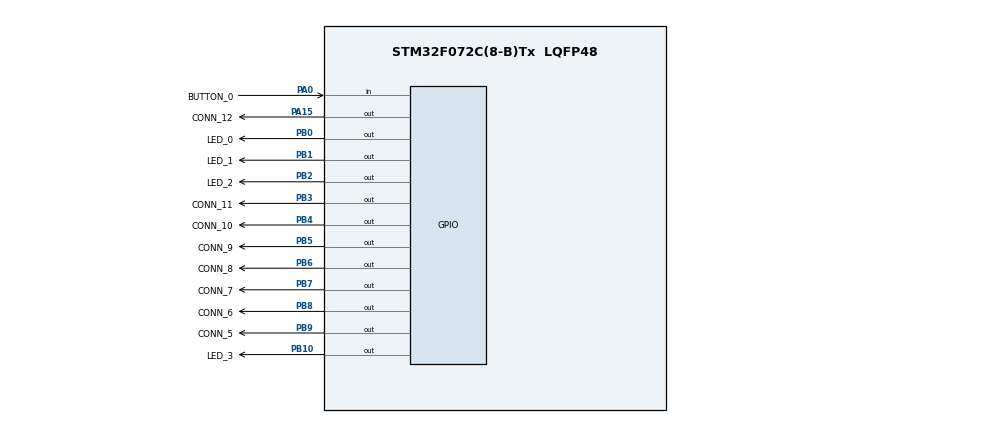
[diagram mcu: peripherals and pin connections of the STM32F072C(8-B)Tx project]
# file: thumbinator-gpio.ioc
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Mcu.Family=STM32F0
Mcu.Name=STM32F072C(8-B)Tx
Mcu.Package=LQFP48
PA0.GPIO_Label=BUTTON_0
PA0.GPIO_PuPd=GPIO_PULLUP
PA0.Signal=GPIO_Input
PA13.Mode=Serial_Wire
PA13.Signal=SYS_SWDIO
PA14.Mode=Serial_Wire
PA14.Signal=SYS_SWCLK
PA15.GPIO_Label=CONN_12
PA15.Signal=GPIO_Output
PB0.GPIO_Label=LED_0
PB0.Signal=GPIO_Output
PB1.GPIO_Label=LED_1
PB1.Signal=GPIO_Output
PB10.GPIO_Label=LED_3
PB10.Signal=GPIO_Output
PB2.GPIO_Label=LED_2
PB2.Signal=GPIO_Output
PB3.GPIO_Label=CONN_11
PB3.Signal=GPIO_Output
PB4.GPIO_Label=CONN_10
PB4.Signal=GPIO_Output
PB5.GPIO_Label=CONN_9
PB5.Signal=GPIO_Output
PB6.GPIO_Label=CONN_8
PB6.Signal=GPIO_Output
PB7.GPIO_Label=CONN_7
PB7.Signal=GPIO_Output
PB8.GPIO_Label=CONN_6
PB8.Signal=GPIO_Output
PB9.GPIO_Label=CONN_5
PB9.Signal=GPIO_Output
ProjectManager.HeapSize=0x200
ProjectManager.StackSize=0x400
ProjectManager.TargetToolchain=SW4STM32
board=thumbinator-gpio

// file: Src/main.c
/**
  ******************************************************************************
  * File Name          : main.c
  * Description        : Main program body
  ******************************************************************************
  ** This notice applies to any and all portions of this file
  * that are not between comment pairs USER CODE BEGIN and
  * USER CODE END. Other portions of this file, whether
  * inserted by the user or by software development tools
  * are owned by their respective copyright owners.
  *
  * COPYRIGHT(c) 2017 STMicroelectronics
  *
  * Redistribution and use in source and binary forms, with or without modification,
  * are permitted provided that the following conditions are met:
  *   1. Redistributions of source code must retain the above copyright notice,
  *      this list of conditions and the following disclaimer.
  *   2. Redistributions in binary form must reproduce the above copyright notice,
  *      this list of conditions and the following disclaimer in the documentation
  *      and/or other materials provided with the distribution.
  *   3. Neither the name of STMicroelectronics nor the names of its contributors
  *      may be used to endorse or promote products derived from this software
  *      without specific prior written permission.
  *
  * THIS SOFTWARE IS PROVIDED BY THE COPYRIGHT HOLDERS AND CONTRIBUTORS "AS IS"
  * AND ANY EXPRESS OR IMPLIED WARRANTIES, INCLUDING, BUT NOT LIMITED TO, THE
  * IMPLIED WARRANTIES OF MERCHANTABILITY AND FITNESS FOR A PARTICULAR PURPOSE ARE
  * DISCLAIMED. IN NO EVENT SHALL THE COPYRIGHT HOLDER OR CONTRIBUTORS BE LIABLE
  * FOR ANY DIRECT, INDIRECT, INCIDENTAL, SPECIAL, EXEMPLARY, OR CONSEQUENTIAL
  * DAMAGES (INCLUDING, BUT NOT LIMITED TO, PROCUREMENT OF SUBSTITUTE GOODS OR
  * SERVICES; LOSS OF USE, DATA, OR PROFITS; OR BUSINESS INTERRUPTION) HOWEVER
  * CAUSED AND ON ANY THEORY OF LIABILITY, WHETHER IN CONTRACT, STRICT LIABILITY,
  * OR TORT (INCLUDING NEGLIGENCE OR OTHERWISE) ARISING IN ANY WAY OUT OF THE USE
  * OF THIS SOFTWARE, EVEN IF ADVISED OF THE POSSIBILITY OF SUCH DAMAGE.
  *
  ******************************************************************************
  */
#include "main.h"
#include "stm32f0xx_hal.h"

/* USER CODE BEGIN PV */
/* Private variables ---------------------------------------------------------*/

/* USER CODE END PV */

void SystemClock_Config(void);
static void MX_GPIO_Init(void);

/* USER CODE BEGIN PFP */
/* Private function prototypes -----------------------------------------------*/

/* USER CODE END PFP */

/* USER CODE BEGIN 0 */

static void next_led(void) {
  static int i = 0;
  i = (i + 1) % 16;
  HAL_GPIO_WritePin(LED_0_GPIO_Port, LED_0_Pin, (i & 1) ? GPIO_PIN_SET : GPIO_PIN_RESET);
  HAL_GPIO_WritePin(LED_1_GPIO_Port, LED_1_Pin, (i & 2) ? GPIO_PIN_SET : GPIO_PIN_RESET);
  HAL_GPIO_WritePin(LED_2_GPIO_Port, LED_2_Pin, (i & 4) ? GPIO_PIN_SET : GPIO_PIN_RESET);
}

/* USER CODE END 0 */

int main(void)
{

  /* MCU Configuration----------------------------------------------------------*/

  /* Reset of all peripherals, Initializes the Flash interface and the Systick. */
  HAL_Init();

  /* Configure the system clock */
  SystemClock_Config();

  /* Initialize all configured peripherals */
  MX_GPIO_Init();

  /* Infinite loop */
  while (1)
  {

  /* USER CODE BEGIN 3 */
    next_led();

    HAL_GPIO_WritePin(LED_3_GPIO_Port, LED_3_Pin, HAL_GPIO_ReadPin(BUTTON_0_GPIO_Port, BUTTON_0_Pin));

    HAL_Delay(250);

  }
  /* USER CODE END 3 */

}

/** System Clock Configuration
*/
void SystemClock_Config(void)
{

  RCC_OscInitTypeDef RCC_OscInitStruct;
  RCC_ClkInitTypeDef RCC_ClkInitStruct;

    /**Initializes the CPU, AHB and APB busses clocks
    */
  RCC_OscInitStruct.OscillatorType = RCC_OSCILLATORTYPE_HSI;
  RCC_OscInitStruct.HSIState = RCC_HSI_ON;
  RCC_OscInitStruct.HSICalibrationValue = 16;
  RCC_OscInitStruct.PLL.PLLState = RCC_PLL_NONE;
  if (HAL_RCC_OscConfig(&RCC_OscInitStruct) != HAL_OK)
  {
    _Error_Handler(__FILE__, __LINE__);
  }

    /**Initializes the CPU, AHB and APB busses clocks
    */
  RCC_ClkInitStruct.ClockType = RCC_CLOCKTYPE_HCLK|RCC_CLOCKTYPE_SYSCLK
                              |RCC_CLOCKTYPE_PCLK1;
  RCC_ClkInitStruct.SYSCLKSource = RCC_SYSCLKSOURCE_HSI;
  RCC_ClkInitStruct.AHBCLKDivider = RCC_SYSCLK_DIV1;
  RCC_ClkInitStruct.APB1CLKDivider = RCC_HCLK_DIV1;

  if (HAL_RCC_ClockConfig(&RCC_ClkInitStruct, FLASH_LATENCY_0) != HAL_OK)
  {
    _Error_Handler(__FILE__, __LINE__);
  }

    /**Configure the Systick interrupt time
    */
  HAL_SYSTICK_Config(HAL_RCC_GetHCLKFreq()/1000);

    /**Configure the Systick
    */
  HAL_SYSTICK_CLKSourceConfig(SYSTICK_CLKSOURCE_HCLK);

  /* SysTick_IRQn interrupt configuration */
  HAL_NVIC_SetPriority(SysTick_IRQn, 0, 0);
}

/** Configure pins as
        * Analog
        * Input
        * Output
        * EVENT_OUT
        * EXTI
*/
static void MX_GPIO_Init(void)
{

  GPIO_InitTypeDef GPIO_InitStruct;

  /* GPIO Ports Clock Enable */
  __HAL_RCC_GPIOA_CLK_ENABLE();
  __HAL_RCC_GPIOB_CLK_ENABLE();

  /*Configure GPIO pin Output Level */
  HAL_GPIO_WritePin(GPIOB, LED_0_Pin|LED_1_Pin|LED_2_Pin|LED_3_Pin
                          |CONN_11_Pin|CONN_10_Pin|CONN_9_Pin|CONN_8_Pin
                          |CONN_7_Pin|CONN_6_Pin|CONN_5_Pin, GPIO_PIN_RESET);

  /*Configure GPIO pin Output Level */
  HAL_GPIO_WritePin(CONN_12_GPIO_Port, CONN_12_Pin, GPIO_PIN_RESET);

  /*Configure GPIO pin : BUTTON_0_Pin */
  GPIO_InitStruct.Pin = BUTTON_0_Pin;
  GPIO_InitStruct.Mode = GPIO_MODE_INPUT;
  GPIO_InitStruct.Pull = GPIO_PULLUP;
  HAL_GPIO_Init(BUTTON_0_GPIO_Port, &GPIO_InitStruct);

  /*Configure GPIO pins : LED_0_Pin LED_1_Pin LED_2_Pin LED_3_Pin
                           CONN_11_Pin CONN_10_Pin CONN_9_Pin CONN_8_Pin
                           CONN_7_Pin CONN_6_Pin CONN_5_Pin */
  GPIO_InitStruct.Pin = LED_0_Pin|LED_1_Pin|LED_2_Pin|LED_3_Pin
                          |CONN_11_Pin|CONN_10_Pin|CONN_9_Pin|CONN_8_Pin
                          |CONN_7_Pin|CONN_6_Pin|CONN_5_Pin;
  GPIO_InitStruct.Mode = GPIO_MODE_OUTPUT_PP;
  GPIO_InitStruct.Pull = GPIO_NOPULL;
  GPIO_InitStruct.Speed = GPIO_SPEED_FREQ_LOW;
  HAL_GPIO_Init(GPIOB, &GPIO_InitStruct);

  /*Configure GPIO pin : CONN_12_Pin */
  GPIO_InitStruct.Pin = CONN_12_Pin;
  GPIO_InitStruct.Mode = GPIO_MODE_OUTPUT_PP;
  GPIO_InitStruct.Pull = GPIO_NOPULL;
  GPIO_InitStruct.Speed = GPIO_SPEED_FREQ_LOW;
  HAL_GPIO_Init(CONN_12_GPIO_Port, &GPIO_InitStruct);

}

void _Error_Handler(char * file, int line)
{
  while(1)
  {
  }
}

/************************ (C) COPYRIGHT STMicroelectronics *****END OF FILE****/
